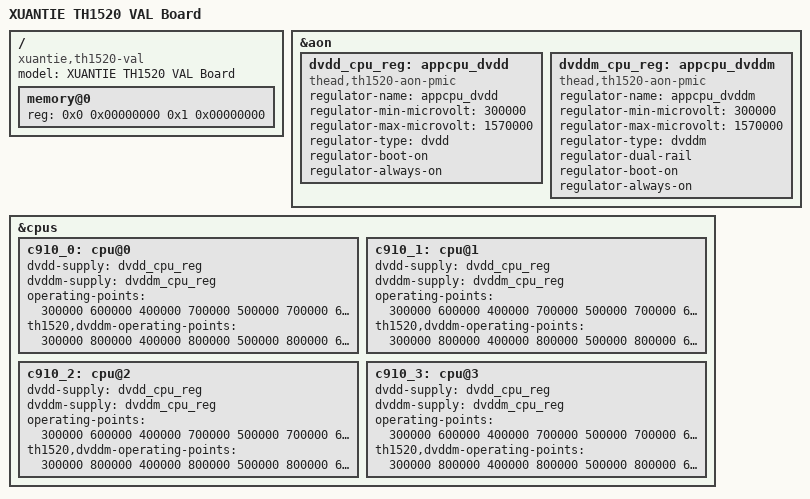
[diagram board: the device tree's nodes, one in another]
/* SPDX-License-Identifier: GPL-2.0 */
/*
 * Copyright (C) 2021-2024 Alibaba Group Holding Limited.
 */

#include "th1520-crash.dtsi"

/ {
	model = "XUANTIE TH1520 VAL Board";
	compatible = "xuantie,th1520-val", "xuantie,th1520", "thead,th1520";

	memory@0 {
		device_type = "memory";
		reg = <0x0 0x00000000 0x1 0x00000000>;
	};
};

&aon {
	dvdd_cpu_reg: appcpu_dvdd {
		compatible = "thead,th1520-aon-pmic";
		regulator-name = "appcpu_dvdd";
		regulator-min-microvolt = <300000>;
		regulator-max-microvolt = <1570000>;
		regulator-type = "dvdd";
		regulator-boot-on;
		regulator-always-on;
	};

	dvddm_cpu_reg: appcpu_dvddm {
		compatible = "thead,th1520-aon-pmic";
		regulator-name = "appcpu_dvddm";
		regulator-min-microvolt = <300000>;
		regulator-max-microvolt = <1570000>;
		regulator-type = "dvddm";
		regulator-dual-rail;
		regulator-boot-on;
		regulator-always-on;
	};
};

&cpus {
	c910_0: cpu@0 {
		dvdd-supply = <&dvdd_cpu_reg>;
		dvddm-supply = <&dvddm_cpu_reg>;

		operating-points = <
			/* kHz    uV */
			300000  600000
			400000  700000
			500000  700000
			600000  700000
			702000  700000
			800000  700000
			900000  800000
			1000000 800000
			1104000 800000
			1200000 800000
			1296000 800000
			1404000 800000
			1500000 800000
			1608000 1000000
			1704000 1000000
			1848000 1000000
		>;
		th1520,dvddm-operating-points = <
			/* kHz   uV */
			300000  800000
			400000  800000
			500000  800000
			600000  800000
			702000  800000
			800000  800000
			900000  800000
			1000000 800000
			1104000 800000
			1200000 800000
			1296000 800000
			1404000 800000
			1500000 800000
			1608000 1000000
			1704000 1000000
			1848000 1000000
		>;
	};
	c910_1: cpu@1 {
		dvdd-supply = <&dvdd_cpu_reg>;
		dvddm-supply = <&dvddm_cpu_reg>;

		operating-points = <
			/* kHz    uV */
			300000  600000
			400000  700000
			500000  700000
			600000  700000
			702000  700000
			800000  700000
			900000  800000
			1000000 800000
			1104000 800000
			1200000 800000
			1296000 800000
			1404000 800000
			1500000 800000
			1608000 1000000
			1704000 1000000
			1848000 1000000
		>;
		th1520,dvddm-operating-points = <
			/* kHz   uV */
			300000  800000
			400000  800000
			500000  800000
			600000  800000
			702000  800000
			800000  800000
			900000  800000
			1000000 800000
			1104000 800000
			1200000 800000
			1296000 800000
			1404000 800000
			1500000 800000
			1608000 1000000
			1704000 1000000
			1848000 1000000
		>;
	};
	c910_2: cpu@2 {
		dvdd-supply = <&dvdd_cpu_reg>;
		dvddm-supply = <&dvddm_cpu_reg>;

		operating-points = <
			/* kHz    uV */
			300000  600000
			400000  700000
			500000  700000
			600000  700000
			702000  700000
			800000  700000
			900000  800000
			1000000 800000
			1104000 800000
			1200000 800000
			1296000 800000
			1404000 800000
			1500000 800000
			1608000 1000000
			1704000 1000000
			1848000 1000000
		>;
		th1520,dvddm-operating-points = <
			/* kHz   uV */
			300000  800000
			400000  800000
			500000  800000
			600000  800000
			702000  800000
			800000  800000
			900000  800000
			1000000 800000
			1104000 800000
			1200000 800000
			1296000 800000
			1404000 800000
			1500000 800000
			1608000 1000000
			1704000 1000000
			1848000 1000000
		>;
	};
	c910_3: cpu@3 {
		dvdd-supply = <&dvdd_cpu_reg>;
		dvddm-supply = <&dvddm_cpu_reg>;

		operating-points = <
			/* kHz    uV */
			300000  600000
			400000  700000
			500000  700000
			600000  700000
			702000  700000
			800000  700000
			900000  800000
			1000000 800000
			1104000 800000
			1200000 800000
			1296000 800000
			1404000 800000
			1500000 800000
			1608000 1000000
			1704000 1000000
			1848000 1000000
		>;
		th1520,dvddm-operating-points = <
			/* kHz   uV */
			300000  800000
			400000  800000
			500000  800000
			600000  800000
			702000  800000
			800000  800000
			900000  800000
			1000000 800000
			1104000 800000
			1200000 800000
			1296000 800000
			1404000 800000
			1500000 800000
			1608000 1000000
			1704000 1000000
			1848000 1000000
		>;
	};
};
